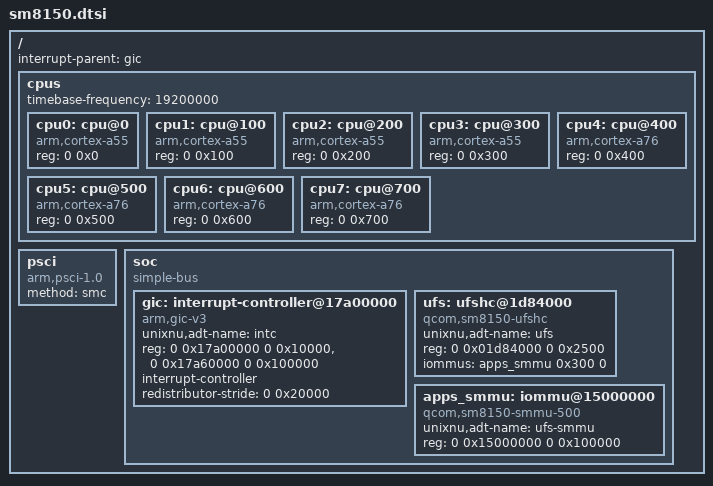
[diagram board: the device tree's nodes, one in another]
// SPDX-License-Identifier: BSD-2-Clause-Patent
// SM8150 resources: Linux sm8150.dtsi; affinities/timer from NABU hardware captures.
/ {
    #address-cells = <2>;
    #size-cells = <2>;
    interrupt-parent = <&gic>;
    cpus {
        #address-cells = <2>;
        #size-cells = <0>;
        timebase-frequency = <19200000>;
        cpu0: cpu@0 { device_type = "cpu"; compatible = "arm,cortex-a55"; reg = <0 0x0>; };
        cpu1: cpu@100 { device_type = "cpu"; compatible = "arm,cortex-a55"; reg = <0 0x100>; };
        cpu2: cpu@200 { device_type = "cpu"; compatible = "arm,cortex-a55"; reg = <0 0x200>; };
        cpu3: cpu@300 { device_type = "cpu"; compatible = "arm,cortex-a55"; reg = <0 0x300>; };
        cpu4: cpu@400 { device_type = "cpu"; compatible = "arm,cortex-a76"; reg = <0 0x400>; };
        cpu5: cpu@500 { device_type = "cpu"; compatible = "arm,cortex-a76"; reg = <0 0x500>; };
        cpu6: cpu@600 { device_type = "cpu"; compatible = "arm,cortex-a76"; reg = <0 0x600>; };
        cpu7: cpu@700 { device_type = "cpu"; compatible = "arm,cortex-a76"; reg = <0 0x700>; };
    };
    psci { compatible = "arm,psci-1.0"; method = "smc"; };
    soc {
        compatible = "simple-bus";
        #address-cells = <2>;
        #size-cells = <2>;
        ranges;
        gic: interrupt-controller@17a00000 {
            compatible = "arm,gic-v3";
            unixnu,adt-name = "intc";
            reg = <0 0x17a00000 0 0x10000>, <0 0x17a60000 0 0x100000>;
            interrupt-controller;
            #interrupt-cells = <3>;
            #address-cells = <0>;
            redistributor-stride = <0 0x20000>;
        };
        ufs: ufshc@1d84000 {
            compatible = "qcom,sm8150-ufshc", "qcom,ufshc";
            unixnu,adt-name = "ufs";
            reg = <0 0x01d84000 0 0x2500>;
            iommus = <&apps_smmu 0x300 0>;
        };
        apps_smmu: iommu@15000000 {
            compatible = "qcom,sm8150-smmu-500", "arm,mmu-500";
            unixnu,adt-name = "ufs-smmu";
            reg = <0 0x15000000 0 0x100000>;
            #iommu-cells = <2>;
        };
    };
};
